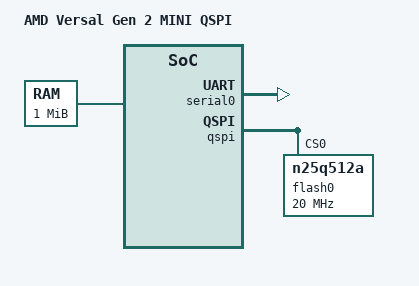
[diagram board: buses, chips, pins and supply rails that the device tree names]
// SPDX-License-Identifier: GPL-2.0
/*
 * dts file for AMD Versal Gen2 mini emmc
 *
 * Copyright (C) 2023 - 2024, Advanced Micro Devices, Inc.
 *
 * Michal Simek <michal.simek@amd.com>
 */

/dts-v1/;

#include <dt-bindings/gpio/gpio.h>

/ {
	compatible = "xlnx,versal2-mini";
	model = "AMD Versal Gen 2 MINI QSPI";
	#address-cells = <2>;
	#size-cells = <2>;

	memory: memory@0 {
		reg = <0 0xBBF00000 0 0x100000>;
		device_type = "memory";
	};

	aliases {
		serial0 = &serial0;
		spi0 = &qspi;
		/* serial0 = &dcc; */
	};

	chosen {
		stdout-path = "serial0:115200";
	};

	clk150: clk150 {
		compatible = "fixed-clock";
		#clock-cells = <0>;
		clock-frequency = <150000000>;
	};

	dcc: dcc {
		compatible = "arm,dcc";
		status = "okay";
		bootph-all;
	};

	amba: axi {
		compatible = "simple-bus";
		bootph-all;
		#address-cells = <2>;
		#size-cells = <2>;
		ranges;

		serial0: serial@f1920000 {
			bootph-all;
			compatible = "arm,pl011", "arm,primecell";
			reg = <0 0xf1920000 0 0x1000>;
			reg-io-width = <4>;
			clock = <1000000>;
			skip-init;
		};

		qspi: spi@f1030000 {
			compatible = "xlnx,versal-qspi-1.0";
			status = "okay";
			clock-names = "ref_clk", "pclk";
			num-cs = <1>;
			reg = <0 0xf1030000 0 0x1000>;
			#address-cells = <1>;
			#size-cells = <0>;
			clocks = <&clk150>, <&clk150>;

			flash0: flash@0 {
				compatible = "n25q512a", "micron,m25p80",
					     "jedec,spi-nor";
				reg = <0>;
				spi-tx-bus-width = <4>;
				spi-rx-bus-width = <4>;
				spi-max-frequency = <20000000>;
			};
		};
	};
};
